# GD32E53x register map
File version: 1.0
CPU: CM33 r0p4, little endian, MPU, FPU, 4 interrupt priority bits
Registers are 32-bit, read-write, reset 0x0 unless marked. A register's access mark holds for its fields unless they carry their own. Offsets are from the block's base; [hi:lo] are bit positions; {n}, {i} and the like mark numbered series.

## FMC — Flash memory controller
Base 0x40022000
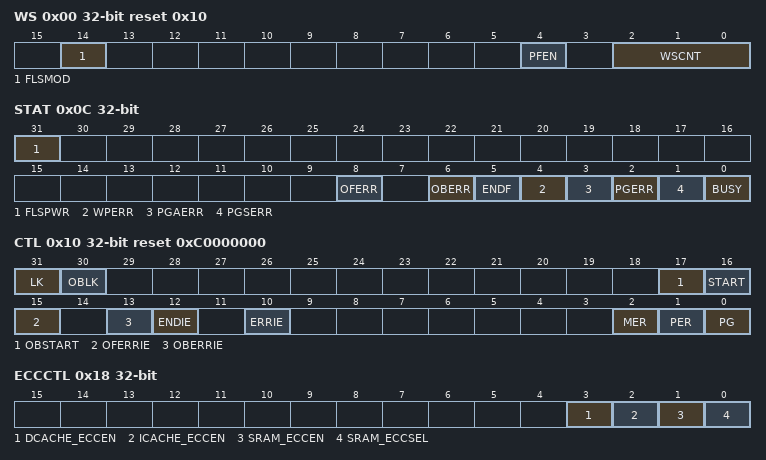
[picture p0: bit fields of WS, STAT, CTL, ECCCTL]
0x00 WS reset 0x10 — Wait state register
  [14] FLSMOD — Flash goto sleep mode or power-down mode when MCU enters deepsleep mode.
  [4] PFEN — Pre-fetch enable
  [2:0] WSCNT — Wait state counter register
0x04 KEY wo — Unlock key register
  [31:0] KEY — FMC_CTL unlock register
0x08 OBKEY wo — Option byte unlock key register
  [31:0] OBKEY — FMC_CTL option bytes operation unlock register
0x0C STAT access per field — Status register
  [31] FLSPWR ro — Flash power ready.
  [8] OFERR rw — Offset error flag bit
  [6] OBERR rw — Option byte read error flag bit.
  [5] ENDF rw — End of operation flag bit
  [4] WPERR rw — Erase / program protection error flag bit.
  [3] PGAERR rw — Program alignment error flag bit
  [2] PGERR rw — Program error flag bit
  [1] PGSERR rw — Program sequence error flag bit.
  [0] BUSY ro — The flash is busy bit
0x10 CTL reset 0xC0000000 — Control register
  [31] LK — FMC_CTL lock bit
  [30] OBLK — FMC_OBCTL lock bit
  [17] OBSTART — Send option byte change command to FMC bit.
  [16] START — Send erase command to the FMC
  [15] OFERRIE — Offset error interrupt enable
  [13] OBERRIE — Option bytes error interrupt enable
  [12] ENDIE — End of operation interrupt enable bit
  [10] ERRIE — Error interrupt enable bit
  [2] MER — Main flash mass erase command bit
  [1] PER — Main flash page erase command bit
  [0] PG — Main flash page program command bit
0x14 ADDR wo — Address register
  [31:0] ADDR — Flash erase/program command address bits
0x18 ECCCTL — ECC control registe
  [3] DCACHE_ECCEN — DCACHE ECC enable
  [2] ICACHE_ECCEN — ICACHE ECC enable
  [1] SRAM_ECCEN — SRAM ECC enable
  [0] SRAM_ECCSEL — SRAM ECC enable control select
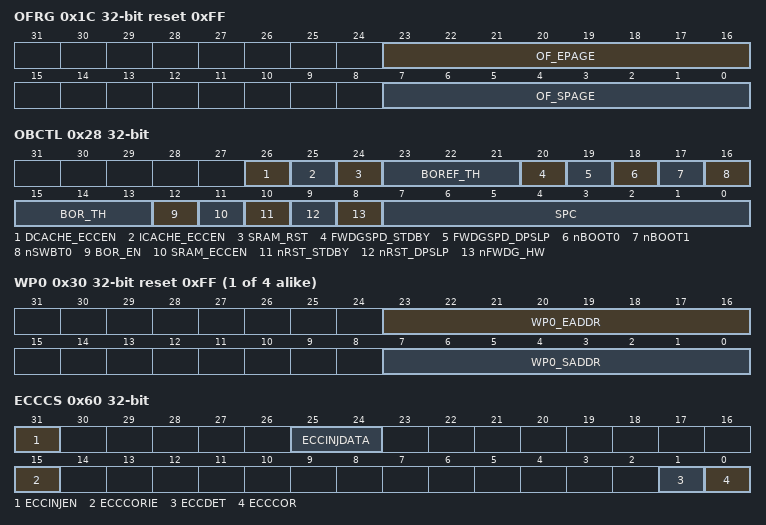
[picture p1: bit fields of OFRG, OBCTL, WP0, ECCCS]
0x1C OFRG reset 0xFF — Offset region register
  [23:16] OF_EPAGE — End page of offset region
  [7:0] OF_SPAGE — Start page of offset region
0x20 OFVR — Offset value register
  [7:0] OF_VALUE — Page offset value.
0x24 SCRCTL reset 0xFFFF — SCR control register
  [15:0] SCRREN — Enable SCR area read
0x28 OBCTL — Option byte control register
  [26] DCACHE_ECCEN — enable DCACHE ECC
  [25] ICACHE_ECCEN — enable ICACHE ECC
  [24] SRAM_RST — sram initialize
  [23:21] BOREF_TH — BOR eflash threshold
  [20] FWDGSPD_STDBY — FWDGT suspend option in standby mode configuration
  [19] FWDGSPD_DPSLP — FWDGT suspend option in deepsleep mode configuration
  [18] nBOOT0 — Boot0 configuration bit
  [17] nBOOT1 — Boot1 configuration bit
  [16] nSWBT0 — Software BOOT0 disable
  [15:13] BOR_TH — BOR_TH Level Selection
  [12] BOR_EN
  [11] SRAM_ECCEN — SRAM ECC disable
  [10] nRST_STDBY — Option byte standby reset value
  [9] nRST_DPSLP — Option byte deepsleep reset value
  [8] nFWDG_HW — Free watchdog configuration bit
  [7:0] SPC — Store SPC of option bytes block after system reset.
0x2C SCRWLK reset 0xFFFF — SCR write lock register
  [15:0] SCRWLK — Enable SCR write lock
{0x30+4i} WP{i} reset 0xFF (i=0..3) — Erase/Program protection regist {i}
  [23:16] WP{i}_EADDR — WP area end page
  [7:0] WP{i}_SADDR — WP area start page
0x44 OTPDATA1_LLK reset 0xFFFFFFFF — OTP DATA1 low block lock register
  [31:0] OTPDATA1_LWLK — OTP USER_DATA1 block write lock
0x48 OTPDATA1_HLK reset 0xFFFFFFFF — OTP DATA1 high block lock register
  [31:0] OTPDATA1_HWLK — OTP DATA1 block write lock
0x4C OTPDATA2_LLK reset 0xFFFFFFFF — OTP DATA2 low block lock register
  [31:0] OTPDATA2_LWLK — OTP USER_DATA2 block write lock
0x50 OTPDATA2_HLK reset 0xFFFFFFFF — OTP DATA2 high block lock register
  [31:0] OTPDATA2_HWLK — OTP USER_DATA2 block write lock
0x54 OTPDATA2_LR_CTL reset 0xFFFFFFFF — OTP DATA2 low read control register
  [31:0] OTPDATA2_LREN — Enable OTP USER_DATA2 block read
0x58 OTPDATA2_HR_CTL reset 0xFFFFFFFF — OTP DATA2 high read control register
  [31:0] OTPDATA2_HREN — Enable OTP USER_DATA2 block read
0x60 ECCCS — ECC control and status register
  [31] ECCINJEN — ECC fault injection enable
  [25:24] ECCINJDATA — this bit field controls the injection of single-bit or double-bit errors into the flash memory
  [15] ECCCORIE — One bit error correct interrupt enable.
  [1] ECCDET — Two-bit errors detect flag. This bit set when two bit errors is detected.
  [0] ECCCOR — One-bit error detected and correct flag.
0x64 ECCADDR — ECC address registe
  [31:0] ECCEAR — ECC error logic address
0x100 PID0 ro — Product ID register 0
  [31:0] PID0 — Product reserved ID code register
0x104 PID1 ro — Product ID register 1
  [31:0] PID1 — Product reserved ID code register
